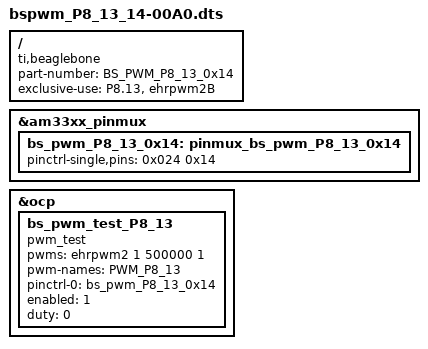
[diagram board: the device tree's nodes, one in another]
/*
 * Copyright (C) 2013 CircuitCo
 * Copyright (C) 2013 Texas Instruments
 *
 * This program is free software; you can redistribute it and/or modify
 * it under the terms of the GNU General Public License version 2 as
 * published by the Free Software Foundation.
 *
 * This is a template-generated file from BoneScript
 */
/dts-v1/;
/plugin/;

/ {
	compatible = "ti,beaglebone", "ti,beaglebone-black";

	/* identification */
	part-number = "BS_PWM_P8_13_0x14";

	/* state the resources this cape uses */
	exclusive-use =
		/* the pin header uses */
		"P8.13",
		/* the hardware IP uses */
		"ehrpwm2B";

	fragment@0 {
		target = <&am33xx_pinmux>;
		__overlay__ {
			bs_pwm_P8_13_0x14: pinmux_bs_pwm_P8_13_0x14 {
				pinctrl-single,pins = <0x024 0x14>;
			};
		};
	};

	fragment@1 {
		target = <&ocp>;
		__overlay__ {
			bs_pwm_test_P8_13 {
				compatible	= "pwm_test";
				pwms 		= <&ehrpwm2 1 500000 1>;
				pwm-names 	= "PWM_P8_13";

				pinctrl-names	= "default";
				pinctrl-0	= <&bs_pwm_P8_13_0x14>;

				enabled		= <1>;
				duty		= <0>;
				status 		= "okay";
			};
		};
	};
};
